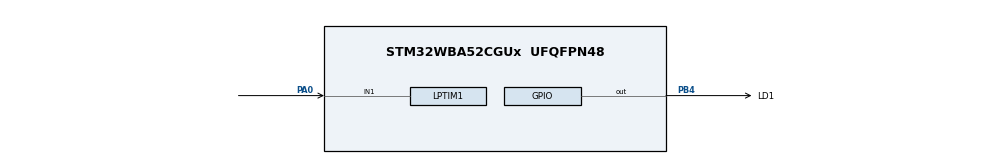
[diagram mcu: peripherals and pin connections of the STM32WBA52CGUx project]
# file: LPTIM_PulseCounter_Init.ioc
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CORTEX_M33_NS.userName=CORTEX_M33
LPTIM1.Period=1000
LPTIM1.TriggerSource=LPTIM_TRIGSOURCE_SOFTWARE
LPTIM1.ULPClockPolarity=LPTIM_CLOCKPOLARITY_RISING
LPTIM1.ULPClockSampleTime=LPTIM_CLOCKSAMPLETIME_DIRECTTRANSITION
LPTIM1.UpdateMode=LPTIM_UPDATE_IMMEDIATE
Mcu.Family=STM32WBA
Mcu.Name=STM32WBA52CGUx
Mcu.Package=UFQFPN48
NVIC.LPTIM1_IRQn=true\:0\:0\:false\:false\:true\:true\:true\:true
NVIC.PriorityGroup=NVIC_PRIORITYGROUP_4
OSC_IN.Mode=HSE-External-Oscillator
OSC_IN.Signal=RCC_OSC_IN
OSC_OUT.Mode=HSE-External-Oscillator
OSC_OUT.Signal=RCC_OSC_OUT
PA0.GPIO_PuPd=GPIO_PULLDOWN
PA0.GPIO_Speed=GPIO_SPEED_FREQ_HIGH
PA0.Mode=Counts_external_clock_with_synchro_01_occur1
PA0.Signal=LPTIM1_IN1
PB4\ (NJTRST).GPIO_Label=LD1
PB4\ (NJTRST).PinState=GPIO_PIN_SET
PB4\ (NJTRST).Signal=GPIO_Output
ProjectManager.HeapSize=0x200
ProjectManager.StackSize=0x400
ProjectManager.TargetToolchain=EWARM V9.20
RCC.ADCFreq_Value=100000000
RCC.AHB5CLKDivider=DIV4
RCC.AHBFreq_Value=100000000
RCC.APB1Freq_Value=100000000
RCC.APB1TimFreq_Value=100000000
RCC.APB2Freq_Value=100000000
RCC.APB2TimFreq_Value=100000000
RCC.CortexFreq_Value=12500000
RCC.HCLKFreq_Value=100000000
RCC.HSE_VALUE=32000000
RCC.HSI_VALUE=16000000
RCC.LPTIM1CLockSelectionVirtual=RCC_LPTIM1CLKSOURCE_LSI
RCC.LSE_VALUE=32768
RCC.PLLFRACN=0
RCC.PLLM=4
RCC.PLLN=25
RCC.PLLSourceVirtual=RCC_PLLSOURCE_HSE
RCC.SYSCLKFreq_VALUE=100000000
RCC.SYSCLKSourceVirtual=RCC_SYSCLKSOURCE_PLLCLK
RCC.VCOOutputFreq_Value=200000000
VP_ICACHE_VS_ICACHE.Mode=DirectMappedCache
VP_PWR_VS_SECSignals.Mode=Security/Privilege
board=custom

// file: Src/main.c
/* USER CODE BEGIN Header */
/**
  ******************************************************************************
  * @file    Examples_LL/LPTIM/LPTIM_PulseCounter_Init/Src/main.c
  * @author  MCD Application Team
  * @brief   This example describes how to use the LPTIM in counter mode
  *          using the STM32WBAxx LPTIM LL API.
  *          Peripheral initialization done using LL initialization function.
  ******************************************************************************
  * @attention
  *
  * Copyright (c) 2022 STMicroelectronics.
  * All rights reserved.
  *
  * This software is licensed under terms that can be found in the LICENSE file
  * in the root directory of this software component.
  * If no LICENSE file comes with this software, it is provided AS-IS.
  *
  ******************************************************************************
  */
/* USER CODE END Header */
#include "main.h"

void SystemClock_Config(void);
static void MX_GPIO_Init(void);
static void MX_LPTIM1_Init(void);
static void MX_ICACHE_Init(void);
/* USER CODE BEGIN PFP */
void Enable_LSI(void);
void EnterStop1Mode(void);
/* USER CODE END PFP */

int main(void)
{

  /* MCU Configuration--------------------------------------------------------*/

  /* Reset of all peripherals, Initializes the Flash interface and the Systick. */

  /* System interrupt init*/
  NVIC_SetPriorityGrouping(NVIC_PRIORITYGROUP_4);

  /* Enable PWR clock interface */

  LL_AHB4_GRP1_EnableClock(LL_AHB4_GRP1_PERIPH_PWR);

  /* Configure the system clock */
  SystemClock_Config();

  /* USER CODE BEGIN SysInit */

   /* Enable the LSI Clock */
  Enable_LSI();
  /* USER CODE END SysInit */

  /* Initialize all configured peripherals */
  MX_GPIO_Init();
  MX_LPTIM1_Init();
  MX_ICACHE_Init();
  /* USER CODE BEGIN 2 */

  /* Enter STOP 1 mode */
  EnterStop1Mode();

  /* USER CODE END 2 */

  /* Infinite loop */
  while (1)
  {

  }
}

void SystemClock_Config(void)
{
  LL_FLASH_SetLatency(LL_FLASH_LATENCY_3);
  while(LL_FLASH_GetLatency()!= LL_FLASH_LATENCY_3)
  {
  }

  LL_PWR_SetRegulVoltageScaling(LL_PWR_REGU_VOLTAGE_SCALE1);
  LL_RCC_HSE_Enable();

   /* Wait till HSE is ready */
  while(LL_RCC_HSE_IsReady() != 1)
  {
  }

   /* Enable Backup domain write access */
  LL_PWR_EnableBkUpAccess();
  LL_RCC_LSI1_SetPrescaler(LL_RCC_LSI_DIV_1);
  LL_RCC_LSI1_Enable();

   /* Wait till LSI1 is ready */
  while(LL_RCC_LSI1_IsReady() != 1)
  {
  }

  LL_RCC_PLL1_ConfigDomain_SYS(LL_RCC_PLL1SOURCE_HSE, 4, 25, 2);
  LL_RCC_PLL1_EnableDomain_PLL1R();
  LL_RCC_PLL1_SetVCOInputRange(LL_RCC_PLLINPUTRANGE_8_16);
  LL_RCC_PLL1_Enable();

   /* Wait till PLL is ready */
  while(LL_RCC_PLL1_IsReady() != 1)
  {
  }

  LL_RCC_SetSysClkSource(LL_RCC_SYS_CLKSOURCE_PLL1R);

   /* Wait till System clock is ready */
  while(LL_RCC_GetSysClkSource() != LL_RCC_SYS_CLKSOURCE_STATUS_PLL1R)
  {
  }

  LL_RCC_SetAHBPrescaler(LL_RCC_SYSCLK_DIV_1);
  LL_RCC_SetAHB5Prescaler(LL_RCC_AHB5_DIV_4);
  LL_RCC_SetAPB1Prescaler(LL_RCC_APB1_DIV_1);
  LL_RCC_SetAPB2Prescaler(LL_RCC_APB2_DIV_1);
  LL_RCC_SetAPB7Prescaler(LL_RCC_APB7_DIV_1);

  LL_Init1msTick(100000000);

  LL_SetSystemCoreClock(100000000);
}

static void MX_ICACHE_Init(void)
{

  /** Enable instruction cache in 1-way (direct mapped cache)
  */
  LL_ICACHE_SetMode(LL_ICACHE_1WAY);
  LL_ICACHE_Enable();

}

static void MX_LPTIM1_Init(void)
{

  LL_GPIO_InitTypeDef GPIO_InitStruct = {0};

  LL_RCC_SetLPTIMClockSource(LL_RCC_LPTIM1_CLKSOURCE_LSI);

  /* Peripheral clock enable */
  LL_APB7_GRP1_EnableClock(LL_APB7_GRP1_PERIPH_LPTIM1);

  LL_AHB2_GRP1_EnableClock(LL_AHB2_GRP1_PERIPH_GPIOA);
  /**LPTIM1 GPIO Configuration
  PA0   ------> LPTIM1_IN1
  */
  GPIO_InitStruct.Pin = LL_GPIO_PIN_0;
  GPIO_InitStruct.Mode = LL_GPIO_MODE_ALTERNATE;
  GPIO_InitStruct.Speed = LL_GPIO_SPEED_FREQ_HIGH;
  GPIO_InitStruct.OutputType = LL_GPIO_OUTPUT_PUSHPULL;
  GPIO_InitStruct.Pull = LL_GPIO_PULL_DOWN;
  GPIO_InitStruct.Alternate = LL_GPIO_AF_0;
  LL_GPIO_Init(GPIOA, &GPIO_InitStruct);

  /* LPTIM1 interrupt Init */
  NVIC_SetPriority(LPTIM1_IRQn, NVIC_EncodePriority(NVIC_GetPriorityGrouping(),0, 0));
  NVIC_EnableIRQ(LPTIM1_IRQn);

  /* USER CODE BEGIN LPTIM1_Init 1 */

  /* LPTIM1 interrupts set-up */
  /* Enable the Autoreload match Interrupt */
  LL_LPTIM_EnableIT_ARRM(LPTIM1);

  /* USER CODE END LPTIM1_Init 1 */
  LL_LPTIM_Enable(LPTIM1);
  LL_LPTIM_ClearFlag_REPOK(LPTIM1);
  LL_LPTIM_SetRepetition(LPTIM1, 0);

   /* Wait till REPOK Flag is ready */
  while(!LL_LPTIM_IsActiveFlag_REPOK(LPTIM1))
  {
  }
  LL_LPTIM_ClearFlag_ARROK(LPTIM1);
  LL_LPTIM_SetAutoReload(LPTIM1, 1000);

   /* Wait till ARROK Flag is ready */
  while(!LL_LPTIM_IsActiveFlag_ARROK(LPTIM1))
  {
  }
  LL_LPTIM_Disable(LPTIM1);
  LL_LPTIM_SetClockSource(LPTIM1, LL_LPTIM_CLK_SOURCE_INTERNAL);
  LL_LPTIM_SetPrescaler(LPTIM1, LL_LPTIM_PRESCALER_DIV1);
  LL_LPTIM_SetUpdateMode(LPTIM1, LL_LPTIM_UPDATE_MODE_IMMEDIATE);
  LL_LPTIM_SetCounterMode(LPTIM1, LL_LPTIM_COUNTER_MODE_EXTERNAL);
  LL_LPTIM_ConfigClock(LPTIM1, LL_LPTIM_CLK_FILTER_NONE, LL_LPTIM_CLK_POLARITY_RISING);
  LL_LPTIM_TrigSw(LPTIM1);
  LL_LPTIM_SetInput1Src(LPTIM1, LL_LPTIM_INPUT1_SRC_GPIO);
  LL_LPTIM_SetInput2Src(LPTIM1, LL_LPTIM_INPUT2_SRC_GPIO);
  /* USER CODE BEGIN LPTIM1_Init 2 */

  /* Enable the LPTIM1 counter */
  LL_LPTIM_Enable(LPTIM1);

  /* Set the Autoreload value */
  LL_LPTIM_SetAutoReload(LPTIM1, 1000);

  /* Start the LPTIM counter in continuous mode */
  LL_LPTIM_StartCounter(LPTIM1, LL_LPTIM_OPERATING_MODE_CONTINUOUS);

  /* USER CODE END LPTIM1_Init 2 */

}

static void MX_GPIO_Init(void)
{
  LL_GPIO_InitTypeDef GPIO_InitStruct = {0};

  /* GPIO Ports Clock Enable */
  LL_AHB2_GRP1_EnableClock(LL_AHB2_GRP1_PERIPH_GPIOA);
  LL_AHB2_GRP1_EnableClock(LL_AHB2_GRP1_PERIPH_GPIOB);

  /**/
  LL_GPIO_SetOutputPin(LD1_GPIO_Port, LD1_Pin);

  /**/
  GPIO_InitStruct.Pin = LD1_Pin;
  GPIO_InitStruct.Mode = LL_GPIO_MODE_OUTPUT;
  GPIO_InitStruct.Speed = LL_GPIO_SPEED_FREQ_LOW;
  GPIO_InitStruct.OutputType = LL_GPIO_OUTPUT_PUSHPULL;
  GPIO_InitStruct.Pull = LL_GPIO_PULL_NO;
  LL_GPIO_Init(LD1_GPIO_Port, &GPIO_InitStruct);

}

/* USER CODE BEGIN 4 */

void Enable_LSI(void)
{
  /* Enable LSI Oscillator */
  LL_RCC_LSI1_SetPrescaler(LL_RCC_LSI_DIV_1);
  LL_RCC_LSI1_Enable();

  while(LL_RCC_LSI1_IsReady() != 1)
  {
  };
}

/**
  * @brief  Function to configure and enter in STOP 1 Mode.
  * @param  None
  * @retval None
  */
void EnterStop1Mode(void)
{
  /* Set low-power mode "Stop" */
  LL_PWR_SetPowerMode(LL_PWR_MODE_STOP1);

  /* Set SLEEPDEEP bit of Cortex System Control Register */
  LL_LPM_EnableDeepSleep();

  /* Request Wait For Interrupt */
  __WFI();
}

/******************************************************************************/
/*   USER IRQ HANDLER TREATMENT                                               */
/******************************************************************************/
/**
  * @brief  LPTimer Autoreload match interrupt processing
  * @param  None
  * @retval None
  */
void LPTimerAutoreloadMatch_Callback(void)
{
  LL_GPIO_TogglePin(LD1_GPIO_Port, LD1_Pin);
}

/* USER CODE END 4 */

void Error_Handler(void)
{
}
